VERSION ""

NS_ :

BS_:

BU_: CAR ANY ACTUATOR SAFETY

CM_ "Kommu Actuator CAN messages starts here";

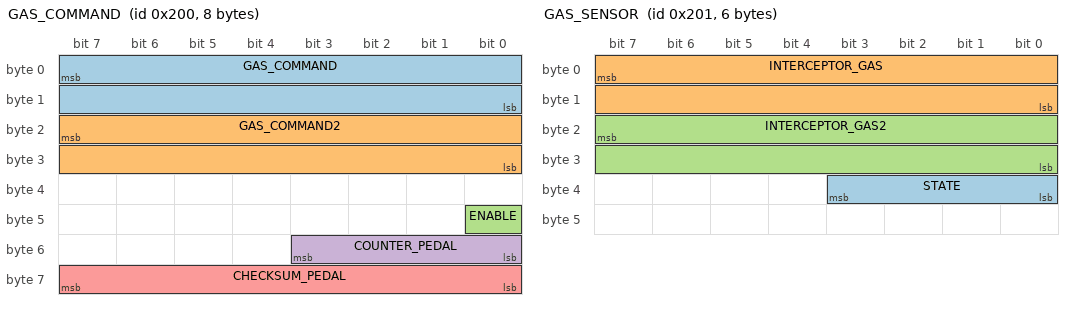
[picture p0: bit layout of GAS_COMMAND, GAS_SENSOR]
BO_ 512 GAS_COMMAND: 8 SAFETY
 SG_ GAS_COMMAND : 7|16@0+ (1,0) [0|1] "" ACTUATOR
 SG_ GAS_COMMAND2 : 23|16@0+ (1,0) [0|1] "" ACTUATOR
 SG_ ENABLE : 40|1@0+ (1,0) [0|1] "" ACTUATOR
 SG_ COUNTER_PEDAL : 51|4@0+ (1,0) [0|15] "" ACTUATOR
 SG_ CHECKSUM_PEDAL : 63|8@0+ (1,0) [0|255] "" ACTUATOR

BO_ 513 GAS_SENSOR: 6 ACTUATOR
 SG_ STATE : 35|4@0+ (1,0) [0|15] "" SAFETY
 SG_ INTERCEPTOR_GAS : 7|16@0+ (0.0007,-0.342) [0|1] "" SAFETY
 SG_ INTERCEPTOR_GAS2 : 23|16@0+ (0.0007,-0.691) [0|1] "" SAFETY

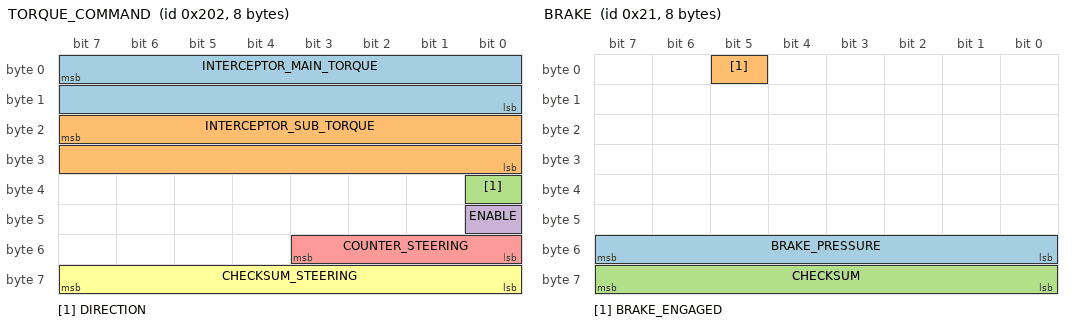
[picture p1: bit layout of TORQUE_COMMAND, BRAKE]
BO_ 514 TORQUE_COMMAND: 8 SAFETY
 SG_ INTERCEPTOR_MAIN_TORQUE : 7|16@0+ (1,0) [0|1] "" ACTUATOR
 SG_ INTERCEPTOR_SUB_TORQUE : 23|16@0+ (1,0) [0|1] "" ACTUATOR
 SG_ DIRECTION : 32|1@0+ (1,0) [0|1] "" ACTUATOR
 SG_ ENABLE : 40|1@0+ (1,0) [0|1] "" ACTUATOR
 SG_ COUNTER_STEERING : 51|4@0+ (1,0) [0|15] "" ACTUATOR
 SG_ CHECKSUM_STEERING : 63|8@0+ (1,0) [0|255] "" ACTUATOR

CM_ "General Perodua CAN messages starts here";

BO_ 33 BRAKE: 8 CAR
 SG_ BRAKE_PRESSURE : 55|8@0+ (1,0) [0|255] "" SAFETY
 SG_ BRAKE_ENGAGED : 5|1@0+ (1,0) [0|1] "" SAFETY
 SG_ CHECKSUM : 63|8@0+ (1,0) [0|255] "" SAFETY

BO_ 37 STEERING_ANGLE_SENSOR: 8 CAR
 SG_ STEER_ANGLE : 46|23@0- (0.00039246467,0) [-500|500] "deg" SAFETY

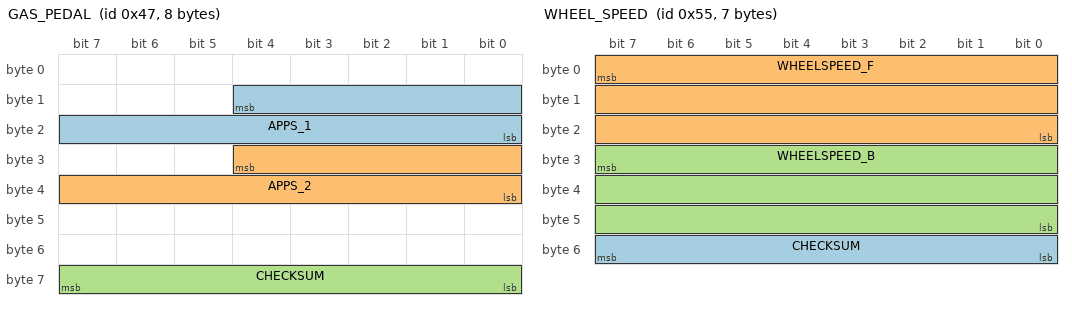
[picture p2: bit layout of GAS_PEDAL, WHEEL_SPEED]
BO_ 71 GAS_PEDAL: 8 CAR
 SG_ APPS_1 : 12|13@0+ (0.00015625,0) [0|1] "" SAFETY
 SG_ APPS_2 : 28|13@0+ (0.00033955857,0) [0|1] "" SAFETY
 SG_ CHECKSUM : 63|8@0+ (1,0) [0|255] "" SAFETY

BO_ 76 GAS_PEDAL_1: 7 CAR
  SG_ GAS_ENGAGED : 1|1@0+ (1,0) [0|1] "" SAFETY

BO_ 85 WHEEL_SPEED: 7 CAR
 SG_ CHECKSUM : 55|8@0+ (1,0) [0|255] "" SAFETY
 SG_ WHEELSPEED_F : 7|24@0+ (0.0000137,0) [0|16777215] "kph" SAFETY
 SG_ WHEELSPEED_B : 31|24@0+ (0.0000036,0) [0|16777215] "kph" SAFETY

BO_ 88 TRANSMISSION: 5 CAR
 SG_ GEAR : 0|6@0+ (1,0) [0|31] "" SAFETY
 SG_ CHECKSUM : 39|8@0+ (1,0) [0|255] "" SAFETY

BO_ 107 STEERING_TORQUE: 4 CAR
 SG_ SUB_TORQUE : 31|8@0+ (1,-111) [0|255] "" SAFETY
 SG_ MAIN_TORQUE : 15|8@0+ (1,0) [0|255] "" SAFETY

BO_ 384 HANDBRAKE: 5 CAR
 SG_ HANDBRAKE_ENGAGED : 0|1@1+ (1,0) [0|1] "" SAFETY
 SG_ CHECKSUM : 31|8@0+ (1,0) [0|255] "" SAFETY

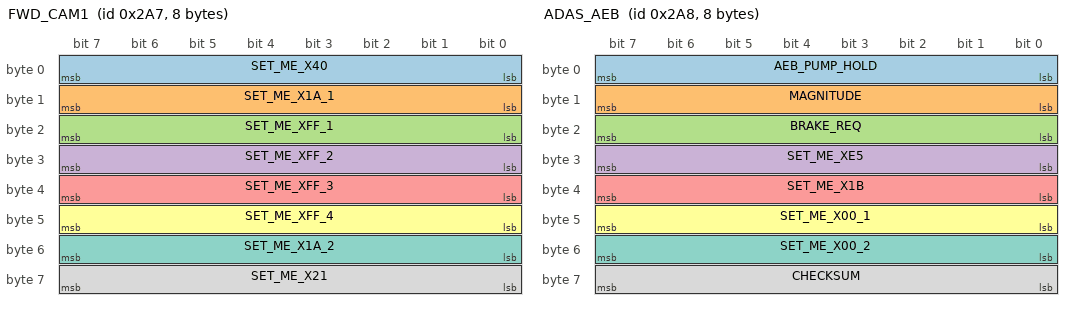
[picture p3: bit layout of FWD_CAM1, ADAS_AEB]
BO_ 679 FWD_CAM1: 8 CAR
 SG_ SET_ME_X40 : 7|8@0+ (1,0) [0|255] "" ANY
 SG_ SET_ME_X1A_1 : 15|8@0+ (1,0) [0|255] "" ANY
 SG_ SET_ME_XFF_1 : 23|8@0+ (1,0) [0|255] "" ANY
 SG_ SET_ME_XFF_2 : 31|8@0+ (1,0) [0|255] "" ANY
 SG_ SET_ME_XFF_3 : 39|8@0+ (1,0) [0|255] "" ANY
 SG_ SET_ME_XFF_4 : 47|8@0+ (1,0) [0|255] "" ANY
 SG_ SET_ME_X1A_2 : 55|8@0+ (1,0) [0|255] "" ANY
 SG_ SET_ME_X21 : 63|8@0+ (1,0) [0|255] "" ANY

BO_ 680 ADAS_AEB: 8 CAR
 SG_ AEB_PUMP_HOLD : 7|8@0+ (1,0) [0|255] "" ANY
 SG_ MAGNITUDE : 15|8@0+ (1,0) [0|255] "" ANY
 SG_ BRAKE_REQ : 23|8@0+ (1,0) [0|255] "" ANY
 SG_ SET_ME_XE5 : 31|8@0+ (1,0) [0|255] "" ANY
 SG_ SET_ME_X1B : 39|8@0+ (1,0) [0|255] "" ANY
 SG_ SET_ME_X00_1 : 47|8@0+ (1,0) [0|255] "" ANY
 SG_ SET_ME_X00_2 : 55|8@0+ (1,0) [0|255] "" ANY
 SG_ CHECKSUM : 63|8@0+ (1,0) [0|255] "" ANY

BO_ 681 ADAS_HUD: 7 ANY
 SG_ AEB_ALARM : 8|1@0+ (1,0) [0|1] "" ANY
 SG_ CHECKSUM : 55|8@0+ (1,0) [0|255] "" ANY

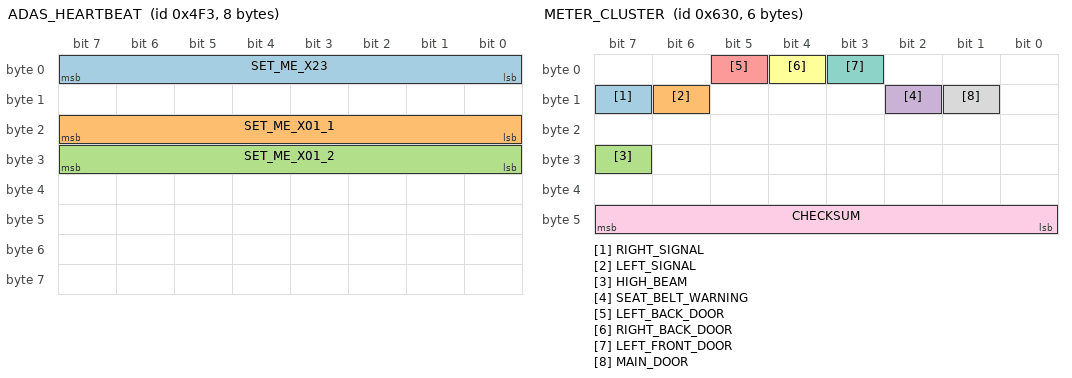
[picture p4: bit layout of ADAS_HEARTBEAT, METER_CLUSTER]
BO_ 1267 ADAS_HEARTBEAT: 8 CAR
 SG_ SET_ME_X23 : 7|8@0+ (1,0) [0|255] "" ANY
 SG_ SET_ME_X01_1 : 23|8@0+ (1,0) [0|255] "" ANY
 SG_ SET_ME_X01_2 : 31|8@0+ (1,0) [0|255] "" ANY

BO_ 1584 METER_CLUSTER: 6 CAR
 SG_ RIGHT_SIGNAL : 15|1@0+ (1,0) [0|1] "" SAFETY
 SG_ LEFT_SIGNAL : 14|1@0+ (1,0) [0|1] "" SAFETY
 SG_ HIGH_BEAM : 31|1@0+ (1,0) [0|1] "" SAFETY
 SG_ SEAT_BELT_WARNING : 10|1@0+ (1,0) [0|1] "" SAFETY
 SG_ LEFT_BACK_DOOR : 5|1@0+ (1,0) [0|1] "" SAFETY
 SG_ RIGHT_BACK_DOOR : 4|1@0+ (1,0) [0|1] "" SAFETY
 SG_ LEFT_FRONT_DOOR : 3|1@0+ (1,0) [0|1] "" SAFETY
 SG_ MAIN_DOOR : 9|1@0+ (1,0) [0|1] "" SAFETY
 SG_ CHECKSUM : 47|8@0+ (1,0) [0|255] "" SAFETY

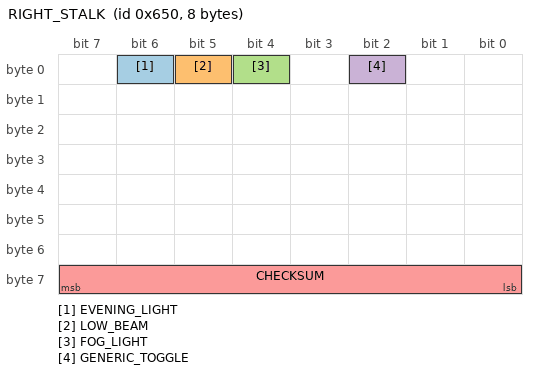
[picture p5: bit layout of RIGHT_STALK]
BO_ 1616 RIGHT_STALK: 8 CAR
 SG_ EVENING_LIGHT : 6|1@0+ (1,0) [0|1] "" SAFETY
 SG_ LOW_BEAM : 5|1@0+ (1,0) [0|1] "" SAFETY
 SG_ FOG_LIGHT : 4|1@0+ (1,0) [0|1] "" SAFETY
 SG_ GENERIC_TOGGLE : 2|1@0+ (1,0) [0|1] "" SAFETY
 SG_ CHECKSUM : 63|8@0+ (1,0) [0|255] "" SAFETY

CM_ SG_ 384 HANDBRAKE_ENGAGED "1 = handbrake engaged";
VAL_ 513 STATE 5 "FAULT_TIMEOUT" 4 "FAULT_STARTUP" 3 "FAULT_SCE" 2 "FAULT_SEND" 1 "FAULT_BAD_CHECKSUM" 0 "NO_FAULT" ;
VAL_ 514 STATE 5 "FAULT_TIMEOUT" 4 "FAULT_STARTUP" 3 "FAULT_SCE" 2 "FAULT_SEND" 1 "FAULT_BAD_CHECKSUM" 0 "NO_FAULT" ;
VAL_ 88 GEAR 32 "P" 16 "R" 8 "N" 4 "D" 2 "D" 1 "D"
